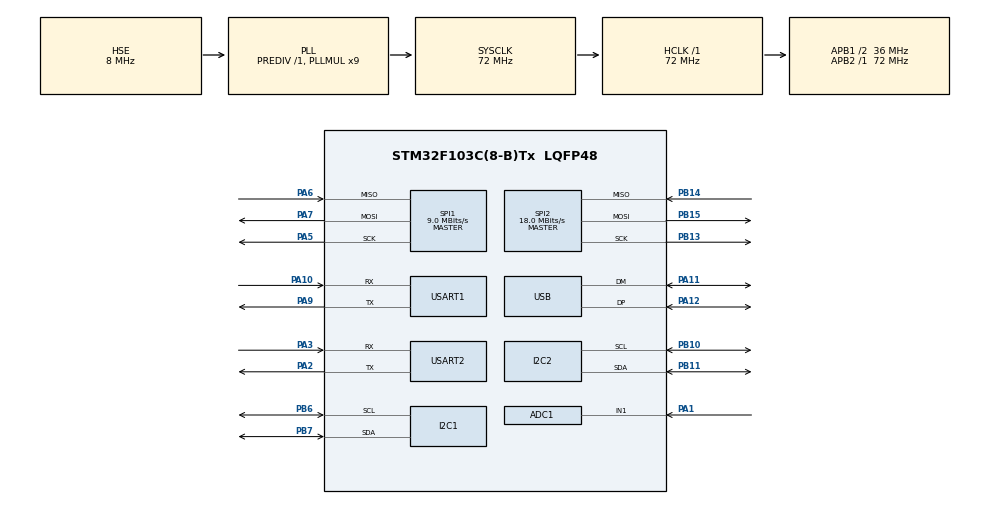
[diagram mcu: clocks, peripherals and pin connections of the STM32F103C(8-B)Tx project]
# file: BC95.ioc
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ADC1.Channel-0\#ChannelRegularConversion=ADC_CHANNEL_1
ADC1.NbrOfConversionFlag=1
ADC1.Rank-0\#ChannelRegularConversion=1
ADC1.SamplingTime-0\#ChannelRegularConversion=ADC_SAMPLETIME_1CYCLE_5
ADC1.master=1
FREERTOS.Tasks01=defaultTask,0,128,StartDefaultTask,Default,NULL
Mcu.Family=STM32F1
Mcu.Name=STM32F103C(8-B)Tx
Mcu.Package=LQFP48
NVIC.PriorityGroup=NVIC_PRIORITYGROUP_4
NVIC.USB_LP_CAN1_RX0_IRQn=true\:5\:0\:false\:false\:true\:true\:false
PA1.Signal=ADCx_IN1
PA10.Mode=Asynchronous
PA10.Signal=USART1_RX
PA11.Mode=Device
PA11.Signal=USB_DM
PA12.Mode=Device
PA12.Signal=USB_DP
PA13.Mode=Serial_Wire
PA13.Signal=SYS_JTMS-SWDIO
PA14.Mode=Serial_Wire
PA14.Signal=SYS_JTCK-SWCLK
PA2.Mode=Asynchronous
PA2.Signal=USART2_TX
PA3.Mode=Asynchronous
PA3.Signal=USART2_RX
PA5.Mode=Full_Duplex_Master
PA5.Signal=SPI1_SCK
PA6.Mode=Full_Duplex_Master
PA6.Signal=SPI1_MISO
PA7.Mode=Full_Duplex_Master
PA7.Signal=SPI1_MOSI
PA9.Mode=Asynchronous
PA9.Signal=USART1_TX
PB10.Mode=I2C
PB10.Signal=I2C2_SCL
PB11.Mode=I2C
PB11.Signal=I2C2_SDA
PB13.Mode=Full_Duplex_Master
PB13.Signal=SPI2_SCK
PB14.Mode=Full_Duplex_Master
PB14.Signal=SPI2_MISO
PB15.Mode=Full_Duplex_Master
PB15.Signal=SPI2_MOSI
PB6.Mode=I2C
PB6.Signal=I2C1_SCL
PB7.Mode=I2C
PB7.Signal=I2C1_SDA
PD0-OSC_IN.Mode=HSE-External-Oscillator
PD0-OSC_IN.Signal=RCC_OSC_IN
PD1-OSC_OUT.Mode=HSE-External-Oscillator
PD1-OSC_OUT.Signal=RCC_OSC_OUT
ProjectManager.HeapSize=0x200
ProjectManager.StackSize=0x400
ProjectManager.TargetToolchain=MDK-ARM V5
RCC.ADCPresc=RCC_ADCPCLK2_DIV6
RCC.AHBFreq_Value=72000000
RCC.APB1CLKDivider=RCC_HCLK_DIV2
RCC.APB1Freq_Value=36000000
RCC.APB1TimFreq_Value=72000000
RCC.APB2Freq_Value=72000000
RCC.APB2TimFreq_Value=72000000
RCC.HCLKFreq_Value=72000000
RCC.PLLMUL=RCC_PLL_MUL9
RCC.SYSCLKFreq_VALUE=72000000
RCC.SYSCLKSource=RCC_SYSCLKSOURCE_PLLCLK
RCC.USBFreq_Value=48000000
RCC.USBPrescaler=RCC_USBCLKSOURCE_PLL_DIV1_5
SH.ADCx_IN1.0=ADC1_IN1,IN1
SPI1.BaudRatePrescaler=SPI_BAUDRATEPRESCALER_8
SPI1.CalculateBaudRate=9.0 MBits/s
SPI1.Direction=SPI_DIRECTION_2LINES
SPI1.Mode=SPI_MODE_MASTER
SPI1.VirtualType=VM_MASTER
SPI2.CalculateBaudRate=18.0 MBits/s
SPI2.Direction=SPI_DIRECTION_2LINES
SPI2.Mode=SPI_MODE_MASTER
SPI2.VirtualType=VM_MASTER
USART1.VirtualMode=VM_ASYNC
USART2.VirtualMode=VM_ASYNC
USB_DEVICE.CLASS_NAME_FS=CDC
USB_DEVICE.VirtualMode=Cdc
USB_DEVICE.VirtualModeFS=Cdc_FS
VP_CRC_VS_CRC.Mode=CRC_Activate
VP_FREERTOS_VS_ENABLE.Mode=Enabled
VP_RTC_VS_RTC_Activate.Mode=RTC_Enabled
VP_USB_DEVICE_VS_USB_DEVICE_CDC_FS.Mode=CDC_FS
board=custom

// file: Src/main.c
/**
  ******************************************************************************
  * @file           : main.c
  * @brief          : Main program body
  ******************************************************************************
  * This notice applies to any and all portions of this file
  * that are not between comment pairs USER CODE BEGIN and
  * USER CODE END. Other portions of this file, whether
  * inserted by the user or by software development tools
  * are owned by their respective copyright owners.
  *
  * Copyright (c) 2018 STMicroelectronics International N.V.
  * All rights reserved.
  *
  * Redistribution and use in source and binary forms, with or without
  * modification, are permitted, provided that the following conditions are met:
  *
  * 1. Redistribution of source code must retain the above copyright notice,
  *    this list of conditions and the following disclaimer.
  * 2. Redistributions in binary form must reproduce the above copyright notice,
  *    this list of conditions and the following disclaimer in the documentation
  *    and/or other materials provided with the distribution.
  * 3. Neither the name of STMicroelectronics nor the names of other
  *    contributors to this software may be used to endorse or promote products
  *    derived from this software without specific written permission.
  * 4. This software, including modifications and/or derivative works of this
  *    software, must execute solely and exclusively on microcontroller or
  *    microprocessor devices manufactured by or for STMicroelectronics.
  * 5. Redistribution and use of this software other than as permitted under
  *    this license is void and will automatically terminate your rights under
  *    this license.
  *
  * THIS SOFTWARE IS PROVIDED BY STMICROELECTRONICS AND CONTRIBUTORS "AS IS"
  * AND ANY EXPRESS, IMPLIED OR STATUTORY WARRANTIES, INCLUDING, BUT NOT
  * LIMITED TO, THE IMPLIED WARRANTIES OF MERCHANTABILITY, FITNESS FOR A
  * PARTICULAR PURPOSE AND NON-INFRINGEMENT OF THIRD PARTY INTELLECTUAL PROPERTY
  * RIGHTS ARE DISCLAIMED TO THE FULLEST EXTENT PERMITTED BY LAW. IN NO EVENT
  * SHALL STMICROELECTRONICS OR CONTRIBUTORS BE LIABLE FOR ANY DIRECT, INDIRECT,
  * INCIDENTAL, SPECIAL, EXEMPLARY, OR CONSEQUENTIAL DAMAGES (INCLUDING, BUT NOT
  * LIMITED TO, PROCUREMENT OF SUBSTITUTE GOODS OR SERVICES; LOSS OF USE, DATA,
  * OR PROFITS; OR BUSINESS INTERRUPTION) HOWEVER CAUSED AND ON ANY THEORY OF
  * LIABILITY, WHETHER IN CONTRACT, STRICT LIABILITY, OR TORT (INCLUDING
  * NEGLIGENCE OR OTHERWISE) ARISING IN ANY WAY OUT OF THE USE OF THIS SOFTWARE,
  * EVEN IF ADVISED OF THE POSSIBILITY OF SUCH DAMAGE.
  *
  ******************************************************************************
  */
#include "main.h"
#include "stm32f1xx_hal.h"
#include "cmsis_os.h"
#include "adc.h"
#include "crc.h"
#include "dma.h"
#include "i2c.h"
#include "rtc.h"
#include "spi.h"
#include "usart.h"
#include "usb_device.h"
#include "gpio.h"

/* USER CODE BEGIN PV */
/* Private variables ---------------------------------------------------------*/

/* USER CODE END PV */

void SystemClock_Config(void);
void MX_FREERTOS_Init(void);

/* USER CODE BEGIN PFP */
/* Private function prototypes -----------------------------------------------*/

/* USER CODE END PFP */

int main(void)
{

  /* MCU Configuration----------------------------------------------------------*/

  /* Reset of all peripherals, Initializes the Flash interface and the Systick. */
  HAL_Init();

  /* Configure the system clock */
  SystemClock_Config();

  /* Initialize all configured peripherals */
  MX_GPIO_Init();
  MX_SPI1_Init();
  MX_SPI2_Init();
  MX_I2C1_Init();
  MX_I2C2_Init();
  MX_USART1_UART_Init();
  MX_USART2_UART_Init();
  MX_ADC1_Init();
  MX_RTC_Init();
  MX_CRC_Init();

  /* Call init function for freertos objects (in freertos.c) */
  MX_FREERTOS_Init();

  /* Start scheduler */
  osKernelStart();

  /* We should never get here as control is now taken by the scheduler */

  /* Infinite loop */
  while (1)
  {

  }

}

void SystemClock_Config(void)
{

  RCC_OscInitTypeDef RCC_OscInitStruct;
  RCC_ClkInitTypeDef RCC_ClkInitStruct;
  RCC_PeriphCLKInitTypeDef PeriphClkInit;

    /**Initializes the CPU, AHB and APB busses clocks
    */
  RCC_OscInitStruct.OscillatorType = RCC_OSCILLATORTYPE_LSI|RCC_OSCILLATORTYPE_HSE;
  RCC_OscInitStruct.HSEState = RCC_HSE_ON;
  RCC_OscInitStruct.HSEPredivValue = RCC_HSE_PREDIV_DIV1;
  RCC_OscInitStruct.HSIState = RCC_HSI_ON;
  RCC_OscInitStruct.LSIState = RCC_LSI_ON;
  RCC_OscInitStruct.PLL.PLLState = RCC_PLL_ON;
  RCC_OscInitStruct.PLL.PLLSource = RCC_PLLSOURCE_HSE;
  RCC_OscInitStruct.PLL.PLLMUL = RCC_PLL_MUL9;
  if (HAL_RCC_OscConfig(&RCC_OscInitStruct) != HAL_OK)
  {
    _Error_Handler(__FILE__, __LINE__);
  }

    /**Initializes the CPU, AHB and APB busses clocks
    */
  RCC_ClkInitStruct.ClockType = RCC_CLOCKTYPE_HCLK|RCC_CLOCKTYPE_SYSCLK
                              |RCC_CLOCKTYPE_PCLK1|RCC_CLOCKTYPE_PCLK2;
  RCC_ClkInitStruct.SYSCLKSource = RCC_SYSCLKSOURCE_PLLCLK;
  RCC_ClkInitStruct.AHBCLKDivider = RCC_SYSCLK_DIV1;
  RCC_ClkInitStruct.APB1CLKDivider = RCC_HCLK_DIV2;
  RCC_ClkInitStruct.APB2CLKDivider = RCC_HCLK_DIV1;

  if (HAL_RCC_ClockConfig(&RCC_ClkInitStruct, FLASH_LATENCY_2) != HAL_OK)
  {
    _Error_Handler(__FILE__, __LINE__);
  }

  PeriphClkInit.PeriphClockSelection = RCC_PERIPHCLK_RTC|RCC_PERIPHCLK_ADC
                              |RCC_PERIPHCLK_USB;
  PeriphClkInit.RTCClockSelection = RCC_RTCCLKSOURCE_LSI;
  PeriphClkInit.AdcClockSelection = RCC_ADCPCLK2_DIV6;
  PeriphClkInit.UsbClockSelection = RCC_USBCLKSOURCE_PLL_DIV1_5;
  if (HAL_RCCEx_PeriphCLKConfig(&PeriphClkInit) != HAL_OK)
  {
    _Error_Handler(__FILE__, __LINE__);
  }

    /**Configure the Systick interrupt time
    */
  HAL_SYSTICK_Config(HAL_RCC_GetHCLKFreq()/1000);

    /**Configure the Systick
    */
  HAL_SYSTICK_CLKSourceConfig(SYSTICK_CLKSOURCE_HCLK);

  /* SysTick_IRQn interrupt configuration */
  HAL_NVIC_SetPriority(SysTick_IRQn, 15, 0);
}

void _Error_Handler(char *file, int line)
{
  while(1)
  {
  }
}

/************************ (C) COPYRIGHT STMicroelectronics *****END OF FILE****/

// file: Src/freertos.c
/* USER CODE BEGIN Header */
/**
  ******************************************************************************
  * File Name          : freertos.c
  * Description        : Code for freertos applications
  ******************************************************************************
  * This notice applies to any and all portions of this file
  * that are not between comment pairs USER CODE BEGIN and
  * USER CODE END. Other portions of this file, whether
  * inserted by the user or by software development tools
  * are owned by their respective copyright owners.
  *
  * Copyright (c) 2018 STMicroelectronics International N.V.
  * All rights reserved.
  *
  * Redistribution and use in source and binary forms, with or without
  * modification, are permitted, provided that the following conditions are met:
  *
  * 1. Redistribution of source code must retain the above copyright notice,
  *    this list of conditions and the following disclaimer.
  * 2. Redistributions in binary form must reproduce the above copyright notice,
  *    this list of conditions and the following disclaimer in the documentation
  *    and/or other materials provided with the distribution.
  * 3. Neither the name of STMicroelectronics nor the names of other
  *    contributors to this software may be used to endorse or promote products
  *    derived from this software without specific written permission.
  * 4. This software, including modifications and/or derivative works of this
  *    software, must execute solely and exclusively on microcontroller or
  *    microprocessor devices manufactured by or for STMicroelectronics.
  * 5. Redistribution and use of this software other than as permitted under
  *    this license is void and will automatically terminate your rights under
  *    this license.
  *
  * THIS SOFTWARE IS PROVIDED BY STMICROELECTRONICS AND CONTRIBUTORS "AS IS"
  * AND ANY EXPRESS, IMPLIED OR STATUTORY WARRANTIES, INCLUDING, BUT NOT
  * LIMITED TO, THE IMPLIED WARRANTIES OF MERCHANTABILITY, FITNESS FOR A
  * PARTICULAR PURPOSE AND NON-INFRINGEMENT OF THIRD PARTY INTELLECTUAL PROPERTY
  * RIGHTS ARE DISCLAIMED TO THE FULLEST EXTENT PERMITTED BY LAW. IN NO EVENT
  * SHALL STMICROELECTRONICS OR CONTRIBUTORS BE LIABLE FOR ANY DIRECT, INDIRECT,
  * INCIDENTAL, SPECIAL, EXEMPLARY, OR CONSEQUENTIAL DAMAGES (INCLUDING, BUT NOT
  * LIMITED TO, PROCUREMENT OF SUBSTITUTE GOODS OR SERVICES; LOSS OF USE, DATA,
  * OR PROFITS; OR BUSINESS INTERRUPTION) HOWEVER CAUSED AND ON ANY THEORY OF
  * LIABILITY, WHETHER IN CONTRACT, STRICT LIABILITY, OR TORT (INCLUDING
  * NEGLIGENCE OR OTHERWISE) ARISING IN ANY WAY OUT OF THE USE OF THIS SOFTWARE,
  * EVEN IF ADVISED OF THE POSSIBILITY OF SUCH DAMAGE.
  *
  ******************************************************************************
  */
/* USER CODE END Header */

#include <stdio.h>
#include <string.h>

#include "FreeRTOS.h"
#include "task.h"
#include "main.h"
#include "cmsis_os.h"

#include "adc.h"
#include "gpio.h"
#include "usart.h"
#include "usb_device.h"
#include "usbd_cdc_if.h"
#include "NBtask.h"

extern void MX_USB_DEVICE_Init(void);
void MX_FREERTOS_Init(void); /* (MISRA C 2004 rule 8.1) */

osThreadId defaultTaskHandle;
void StartDefaultTask(void const * argument);

osThreadId USBTaskHandle;
void StartUSBTask(void const * argument);

osThreadId NBTaskHandle;
void StartNBTask1(void const * argument);

void MX_FREERTOS_Init(void) {

  //osThreadDef(defaultTask, StartDefaultTask, osPriorityNormal, 1, 128);
  //defaultTaskHandle = osThreadCreate(osThread(defaultTask), NULL);
  //osThreadDef(USBTask, StartUSBTask, osPriorityNormal, 2, 128);
  //USBTaskHandle = osThreadCreate(osThread(USBTask), NULL);
	osThreadDef(NBTask, StartNBTask, osPriorityNormal, 4, 312);
	NBTaskHandle = osThreadCreate(osThread(NBTask), NULL);

}

void StartDefaultTask(void const * argument)
{
  /* init code for USB_DEVICE */
  MX_USB_DEVICE_Init();

  /* USER CODE BEGIN StartDefaultTask */
  /* Infinite loop */
  for(;;)
  {
		osDelay(500);
		vTaskSuspendAll();
		HAL_GPIO_TogglePin(GPIOC,GPIO_PIN_13);
		printf("default UART1 task \t\n");
		xTaskResumeAll();
  }
  /* USER CODE END StartDefaultTask */
}

void StartUSBTask(void const * argument)
{
  /* init code for USB_DEVICE */
	MX_USB_DEVICE_Init();
	uint8_t USBTxBuffer[] = "Rex qitas STM32 Virtual COM Port\r\n";
  /* USER CODE BEGIN StartDefaultTask */
  /* Infinite loop */
  for(;;)
  {
		osDelay(2000);
		vTaskSuspendAll();
		CDC_Transmit_FS(USBTxBuffer, strlen((char *)USBTxBuffer));
		xTaskResumeAll();
  }
  /* USER CODE END StartDefaultTask */
}

/************************ (C) COPYRIGHT STMicroelectronics *****END OF FILE****/
